# max32672 register map
Vendor: Maxim-Integrated; Series: ARMCM4; File version: 1.0
CPU: CM4 r2p1, little endian, MPU, FPU, 3 interrupt priority bits
Registers are 32-bit, read-write, reset 0x0 unless marked. A register's access mark holds for its fields unless they carry their own. Offsets are from the block's base; [hi:lo] are bit positions; {n}, {i} and the like mark numbered series; 'fields as' and 'values as' point back to an identical list.

## SYS_AESKEYS — System AES Key Registers.
Base 0x40205000
{0x0+4i} KEY{i} (i=0..7) — AES Key {i}.

## USR_AESKEYS — User AES Key Registers.
Base 0x40005000
0x00 SRAM_KEY — AES SRAM KEY
0x20 CODE_KEY — AES CODE Key
0x40 DATA_KEY — AES DATA KEY

## FCR — Function Control Register.
Base 0x40000800
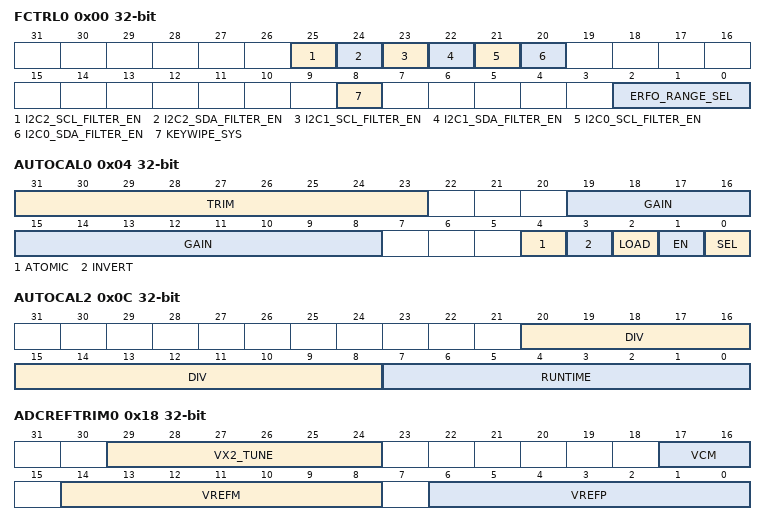
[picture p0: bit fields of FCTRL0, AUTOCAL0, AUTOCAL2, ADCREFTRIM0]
0x00 FCTRL0 — Register 0.
  [25] I2C2_SCL_FILTER_EN — I2C2 SCL Glitch Filter Enable.
    0=dis (Filter disabled.); 1=en (Filter enabled.)
  [24] I2C2_SDA_FILTER_EN — I2C2 SDA Glitch Filter Enable.
    0=dis (Filter disabled.); 1=en (Filter enabled.)
  [23] I2C1_SCL_FILTER_EN — I2C1 SCL Glitch Filter Enable.
    0=dis (Filter disabled.); 1=en (Filter enabled.)
  [22] I2C1_SDA_FILTER_EN — I2C1 SDA Glitch Filter Enable.
    0=dis (Filter disabled.); 1=en (Filter enabled.)
  [21] I2C0_SCL_FILTER_EN — I2C0 SCL Glitch Filter Enable.
    0=dis (Filter disabled.); 1=en (Filter enabled.)
  [20] I2C0_SDA_FILTER_EN — I2C0 SDA Glitch Filter Enable.
    0=dis (Filter disabled.); 1=en (Filter enabled.)
  [8] KEYWIPE_SYS
  [2:0] ERFO_RANGE_SEL — 14MHz-32MHz ERFO Frequency Range Select.
0x04 AUTOCAL0 — Register 1.
  [31:23] TRIM — 150MHz HFIO Auto Calibration Trim
  [19:8] GAIN — MU value.
  [4] ATOMIC — Atomic mode.
    0=not (Not Running.); 1=run (Running.)
  [3] INVERT — Invert Gain.
    0=not (do Not invert trim step.); 1=Invert trim step
  [2] LOAD — Load Trim.
  [1] EN — Autocalibration Run.
    0=not (Not Running.); 1=run (Running.)
  [0] SEL — Auto-calibration Enable.
    0=dis (Disabled.); 1=en (Enabled.)
0x08 AUTOCAL1 — Register 2.
  [8:0] INITIAL — 100MHz IPO Trim Automatic Calibration Initial Trim.
0x0C AUTOCAL2 — Register 3.
  [20:8] DIV — 100MHz IPO Trim Automatic Calibration Divide Factor.
  [7:0] RUNTIME — 100MHz IPO Trim Automatic Calibration Run Time.
0x10 TS0 ro — Register 4.
  [11:0] GAIN — Unsigned gain for temp sensor normalization
0x14 TS1 ro — Register 5.
  [31:0] OFFSET — Signed offset for temp sensor correction
0x18 ADCREFTRIM0 — ADC Reference Trim 0
  [29:24] VX2_TUNE — Controls tuning capacitor in fine DAC (offset binary)
  [17:16] VCM — Trimming code for VCM output of reference buffer
  [14:8] VREFM — Trimming code for VREFM output of reference buffer
  [6:0] VREFP — Trimming code for VREFP output of reference buffer
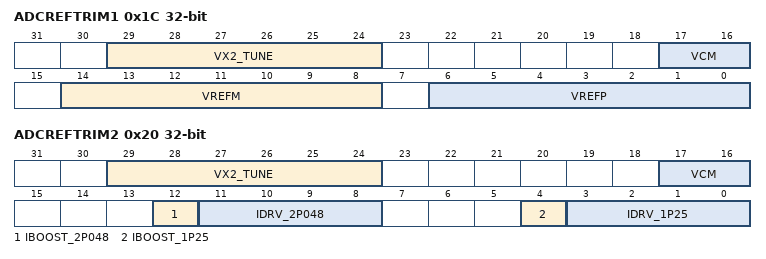
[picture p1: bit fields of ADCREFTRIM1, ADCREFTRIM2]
0x1C ADCREFTRIM1 — ADC Reference Trim 1
  fields as ADCREFTRIM0
0x20 ADCREFTRIM2 — ADC Reference Trim 2
  [29:24] VX2_TUNE — Controls tuning capacitor in fine DAC (offset binary)
  [17:16] VCM — Trimming code for VCM output of reference buffer
  [12] IBOOST_2P048 — Trimming value for extra drive current in reference buffer outputs. 2.048V
  [11:8] IDRV_2P048 — Trimming code for reference buffer drive strength. 2.048V
  [4] IBOOST_1P25 — Trimming value for extra drive current in reference buffer outputs. 2.048V
  [3:0] IDRV_1P25 — Trimming code for reference buffer drive strength. 1.25V
0x24 ERFOKS — External Radio Frequency Oscillator Kick Start Control Register.
  [15:0] CTRL — Kickstart Control for ERFO.

## FLC — Flash Memory Control.
Base 0x40029000; register names take the prefix FLSH_
Same registers: FLC1 0x40029400
0x00 ADDR — Flash Write Address.
  [31:0] ADDR — Address for next operation.
0x04 CLKDIV reset 0x64 — Flash Clock Divide. The clock (PLL0) is divided by this value to generate a 1 MHz clock for Flash controller.
  [7:0] CLKDIV — Flash Clock Divide. The clock is divided by this value to generate a 1MHz clock for flash controller.
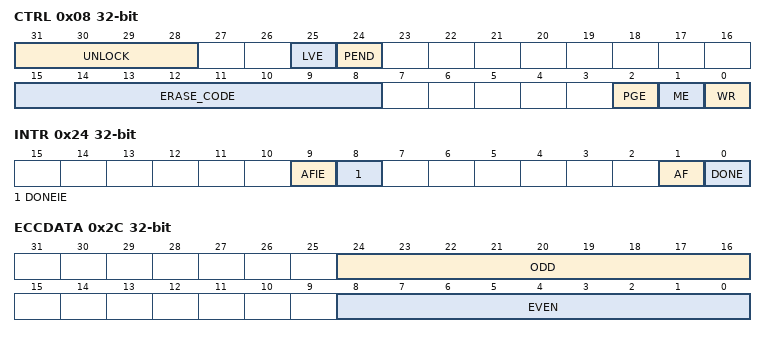
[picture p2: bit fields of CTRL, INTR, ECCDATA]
0x08 CTRL — Flash Control Register.
  [31:28] UNLOCK — Flash Unlock. The correct unlock code must be written to these four bits before any Flash write or erase operation is allowed.
    2=unlocked (Flash Unlocked.); 3=locked (Flash Locked.)
  [25] LVE — Low Voltage enable.
  [24] PEND ro — Flash Pending. When Flash operation is in progress (busy), Flash reads and writes will fail. When PEND is set, write to all Flash registers, with exception of the Flash interrupt register, are ignored.
    0=idle; 1=busy
  [15:8] ERASE_CODE — Erase Code. The ERASE_CODE must be set up property before erase operation can be initiated. These bits are automatically cleared after the operation is complete.
    0=nop (No operation.); 85=erasePage (Enable Page Erase.); 170=eraseAll (Enable Mass Erase. The debug port must be enabled.)
  [2] PGE — Page Erase. This bit is automatically cleared after the operation.
    0=complete (No operation/complete.); 1=Start operation
  [1] ME — Mass Erase. This bit is automatically cleared after the operation.
    0=complete (No operation/complete.); 1=Start operation
  [0] WR — Write. This bit is automatically cleared after the operation.
    0=complete (No operation/complete.); 1=Start operation
0x24 INTR — Flash Interrupt Register.
  [9] AFIE — Flash Done Interrupt Enable.
    0=disable; 1=enable
  [8] DONEIE — Flash Done Interrupt Enable.
    0=disable; 1=enable
  [1] AF — Flash Access Fail. This bit is set when an attempt is made to write the flash while the flash is busy or the flash is locked. This bit can only be set to 1 by hardware.
    0=noError (No Failure.); 1=error (Failure occurs.)
  [0] DONE — Flash Done Interrupt. This bit is set to 1 upon Flash write or erase completion.
    0=inactive (No interrupt is pending.); 1=pending (An interrupt is pending.)
0x2C ECCDATA
  [24:16] ODD — Error Correction Code Even Data.
  [8:0] EVEN — Error Correction Code Odd Data.
{0x30+4i} DATA[{i}] (i=0..3) — Flash Write Data.
  [31:0] DATA — Data next operation.
0x40 ACTRL wo — Access Control Register. Writing the ACTRL register with the following values in the order shown, allows read and write access to the system and user Information block: pflc-actrl = 0x3a7f5ca3; pflc-actrl = 0xa1e34f20; pflc-actrl = 0x9608b2c1. When unlocked, a write of any word will disable access to system and user information block. Readback of this register is always zero.
  [31:0] ACTRL — Access control.
0x80 WELR0
  [31:0] WELR0 — Access control.
0x88 WELR1
  [31:0] WELR1 — Access control.
0x90 RLR0
  [31:0] RLR0 — Access control.
0x98 RLR1
  [31:0] RLR1 — Access control.
